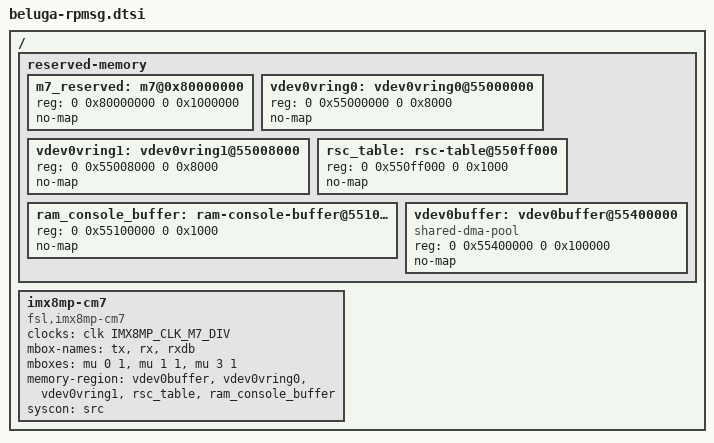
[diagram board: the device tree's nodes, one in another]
// SPDX-License-Identifier: (GPL-2.0 OR MIT)
/*
 * Copyright 2020 NXP
 * Copyright (C) 2022 Leica Geosystems AG
 */

/ {
	reserved-memory {
		#address-cells = <2>;
		#size-cells = <2>;
		ranges;

		m7_reserved: m7@0x80000000 {
			reg = <0 0x80000000 0 0x1000000>;
			no-map;
		};

		vdev0vring0: vdev0vring0@55000000 {
			reg = <0 0x55000000 0 0x8000>;
			no-map;
		};

		vdev0vring1: vdev0vring1@55008000 {
			reg = <0 0x55008000 0 0x8000>;
			no-map;
		};

		rsc_table: rsc-table@550ff000 {
			reg = <0 0x550ff000 0 0x1000>;
			no-map;
		};

		ram_console_buffer: ram-console-buffer@55100000 {
			reg = <0 0x55100000 0 0x1000>;
			no-map;
		};

		vdev0buffer: vdev0buffer@55400000 {
			compatible = "shared-dma-pool";
			reg = <0 0x55400000 0 0x100000>;
			no-map;
		};
	};

	imx8mp-cm7 {
		compatible = "fsl,imx8mp-cm7";
		clocks = <&clk IMX8MP_CLK_M7_DIV>;
		mbox-names = "tx", "rx", "rxdb";
		mboxes = <&mu 0 1
			  &mu 1 1
			  &mu 3 1>;
		memory-region = <&vdev0buffer>, <&vdev0vring0>, <&vdev0vring1>,
				<&rsc_table>, <&ram_console_buffer>;
		status = "okay";
		syscon = <&src>;
	};
};
